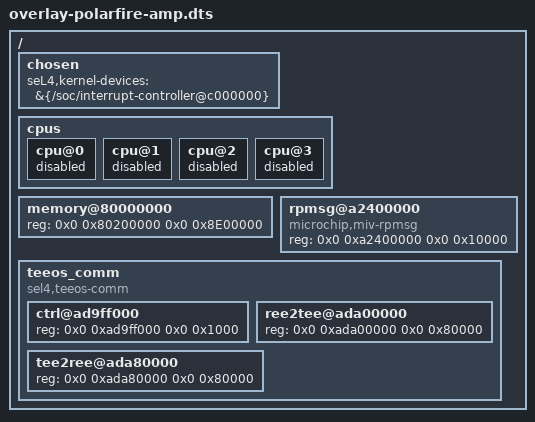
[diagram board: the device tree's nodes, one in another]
 /*
 * Copyright 2020, DornerWorks
 * Copyright 2021, Unikie
 *
 * SPDX-License-Identifier: GPL-2.0-only
 */

/ {
	chosen {
		seL4,kernel-devices =
		    &{/soc/interrupt-controller@c000000};
	};

	cpus {
		cpu@0 { /* HSS */
			status = "disabled";
		};
		cpu@1 { /* reserved for REE */
			status = "disabled";
		};
		cpu@2 { /* reserved for REE */
			status = "disabled";
		};
		cpu@3 { /* reserved for REE */
			status = "disabled";
		};
	};

    /* Reserve 2 MiB for SBI at the start of RAM (0x80000000 - 0x80200000). This
     * is exactly one "megapage" in the MMU table. It leaves plenty of space for
     * further SBI experimenting, given the known usage (as of June 2021) is:
     * - BBL: 76 KiB (= 0x13000)
     * - OpenSBI: 128 KiB (= 0x20000) with PMP protection
     *
     * REE memory starting from 0x89000000
     */

	memory@80000000 { /* overwrite uses same label as in dts file */
		reg = <0x0 0x80200000 0x0 0x8E00000>;
	};

	/* rpmsg-lite supports only 32bit address range. RL_WORD_ALIGN_-macros
	 * shrink address to uint32_t
	 *
	 * I.e. area MUST be located in lower DDR range.
	 */
	rpmsg@a2400000 {
		compatible = "microchip,miv-rpmsg";
		reg =  <0x0 0xa2400000 0x0 0x10000>; // 64Kb reserved for vrings
	};

	teeos_comm {
		#address-cells = <2>;
		#size-cells = <2>;
		compatible = "sel4,teeos-comm";
		ranges;
		ctrl@ad9ff000 {
			reg = <0x0 0xad9ff000 0x0 0x1000>;
		};
		ree2tee@ada00000 {
			reg = <0x0 0xada00000 0x0 0x80000>;
		};
		tee2ree@ada80000 {
			reg = <0x0 0xada80000 0x0 0x80000>;
		};
	};

};
